# APM32F411 register map
Vendor: Geehy; File version: 2024.11.05
CPU: CM4 r1p0, little endian, 3 interrupt priority bits
Registers are 32-bit, read-write, reset 0x0 unless marked. A register's access mark holds for its fields unless they carry their own. Offsets are from the block's base; [hi:lo] are bit positions; {n}, {i} and the like mark numbered series.

## OTG_FS_PWRCLK — USB on the go full speed
Base 0x50000E00
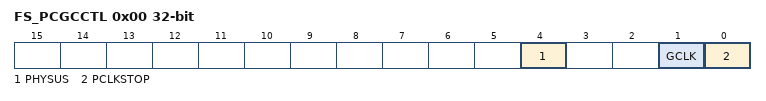
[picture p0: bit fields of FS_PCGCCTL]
0x00 FS_PCGCCTL — OTG_FS power and clock gating control register
  [4] PHYSUS — PHY Suspended
  [1] GCLK — Gate HCLK
  [0] PCLKSTOP — Stop PHY clock

## PMU — Power control
Base 0x40007000
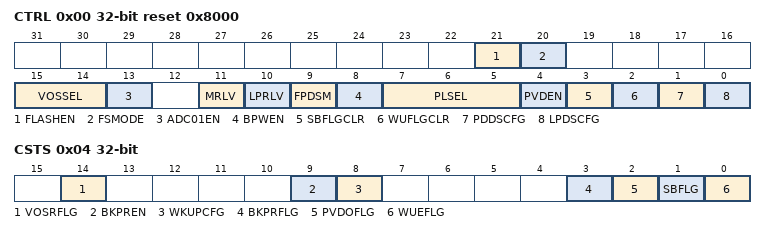
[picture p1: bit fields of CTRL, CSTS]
0x00 CTRL reset 0x8000 — power control register
  [21] FLASHEN — Flash Interface Enable
  [20] FSMODE — Force Flash Sleep Mode
  [15:14] VOSSEL — Regulator Voltage Scaling Output Selection
  [13] ADC01EN — ADC Option 1 Enable
  [11] MRLV — Main Regulator Low Voltage in Stop Mode
  [10] LPRLV — Low Power Regulator Low Voltage in Stop Mode
  [9] FPDSM — Flash power down in Stop mode
  [8] BPWEN — Backup Domain Write Access Enable
  [7:5] PLSEL — PVD level selection
  [4] PVDEN — Power voltage detector enable
  [3] SBFLGCLR — Clear standby flag
  [2] WUFLGCLR — Clear wakeup flag
  [1] PDDSCFG — Power down deepsleep
  [0] LPDSCFG — Low-power deep sleep
0x04 CSTS access per field — power control/status register
  [14] VOSRFLG rw — Regulator voltage scaling output selection ready bit
  [9] BKPREN rw — Backup regulator enable
  [8] WKUPCFG rw — Enable WKUP pin
  [3] BKPRFLG ro — Backup regulator ready
  [2] PVDOFLG ro — PVD output
  [1] SBFLG ro — Standby flag
  [0] WUEFLG ro — Wakeup flag

## QSPI — Quick Serial peripheral interface
Base 0xA0001000
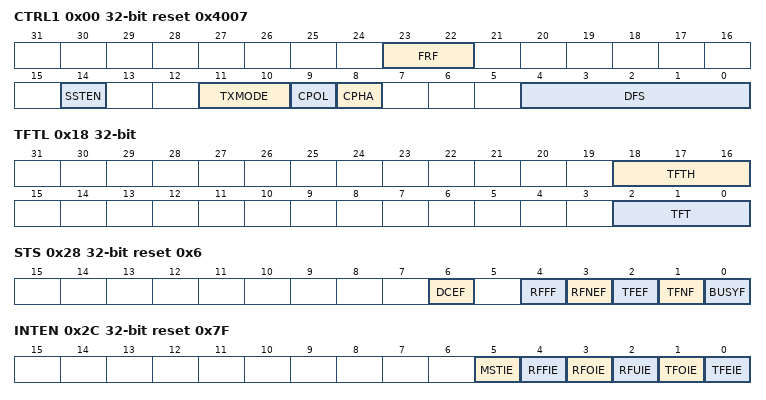
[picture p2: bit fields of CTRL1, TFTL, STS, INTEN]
0x00 CTRL1 reset 0x4007 — Control register 1
  [23:22] FRF, [14] SSTEN, [11:10] TXMODE, [9] CPOL, [8] CPHA, [4:0] DFS
0x04 CTRL2 — Control register 2
  [15:0] NDF
0x08 SSIEN — QSPI Enable register
  [0] EN
0x10 SLAEN — QSPI Slave enable register
  [0] SLAEN
0x14 BR — Baudrate register
  [15:0] CLKDIV
0x18 TFTL — Transmission FIFO threshhold level register
  [18:16] TFTH, [2:0] TFT
0x1C RFTL — Reception FIFO threshhold level register
  [2:0] RFT
0x20 TFL — Transmission FIFO level register
  [2:0] TFL
0x24 RFL — Reception FIFO level register
  [2:0] RFL
0x28 STS reset 0x6 — Status register
  [6] DCEF, [4] RFFF, [3] RFNEF, [2] TFEF, [1] TFNF, [0] BUSYF
0x2C INTEN reset 0x7F — Interrupt enable register
  [5] MSTIE, [4] RFFIE, [3] RFOIE, [2] RFUIE, [1] TFOIE, [0] TFEIE
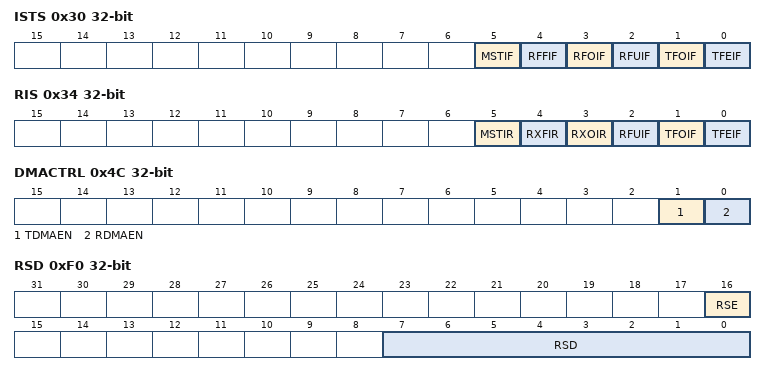
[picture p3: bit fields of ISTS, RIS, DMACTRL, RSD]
0x30 ISTS ro — Interrupt status register
  [5] MSTIF, [4] RFFIF, [3] RFOIF, [2] RFUIF, [1] TFOIF, [0] TFEIF
0x34 RIS ro — Raw interrupt register
  [5] MSTIR, [4] RXFIR, [3] RXOIR, [2] RFUIF, [1] TFOIF, [0] TFEIF
0x38 TFOIC ro — Transmission FIFO overflow interrupt clear register
  [0] TFOIC
0x3C RFOIC ro — Reception FIFO overflow interrupt clear register
  [0] RFOIC
0x40 RFUIC ro — Reception FIFO underflow interrupt clear register
  [0] RFUIC
0x44 MIC ro — Master interrupt clear register
  [0] MIC
0x48 ICF ro — Interrupt clear register
  [0] ICF
0x4C DMACTRL — dma control register
  [1] TDMAEN — Transmit DMA Enable
  [0] RDMAEN — Receive DMA Enable
0x50 DMATDL — dma tx data level register
  [2:0] DMATDL
0x54 DMARDL — dma rx data level register
  [2:0] DMARDL
0x60 DATA
0xF0 RSD — Reception sample register
  [16] RSE, [7:0] RSD
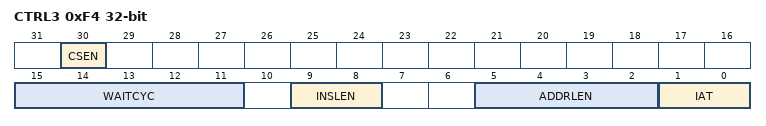
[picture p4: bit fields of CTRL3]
0xF4 CTRL3 — Control register 3
  [30] CSEN, [15:11] WAITCYC, [9:8] INSLEN, [5:2] ADDRLEN, [1:0] IAT
0x200 IOSW — IO switch register
  [0] IOSW — I/O switch

## RNG — Random number generator
Base 0x50060800
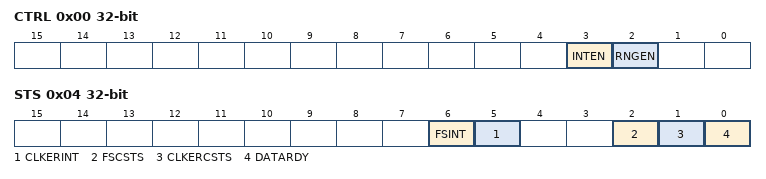
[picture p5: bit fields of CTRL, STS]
0x00 CTRL — control register
  [3] INTEN — Interrupt enable
  [2] RNGEN — Random number generator enable
0x04 STS access per field — status register
  [6] FSINT rw — Seed error interrupt status
  [5] CLKERINT rw — Clock error interrupt status
  [2] FSCSTS ro — Seed error current status
  [1] CLKERCSTS ro — Clock error current status
  [0] DATARDY ro — Data ready
0x08 DATA ro
  [31:0] DATA — Random data

## SYSCFG — System configuration controller
Base 0x40013800
0x00 MMSEL — memory remap register
  [1:0] MMSEL — Memory Mapping Select
0x04 PMCFG — peripheral mode configuration register
  [16] ADCx02EN — ADCx Option 2 Enable
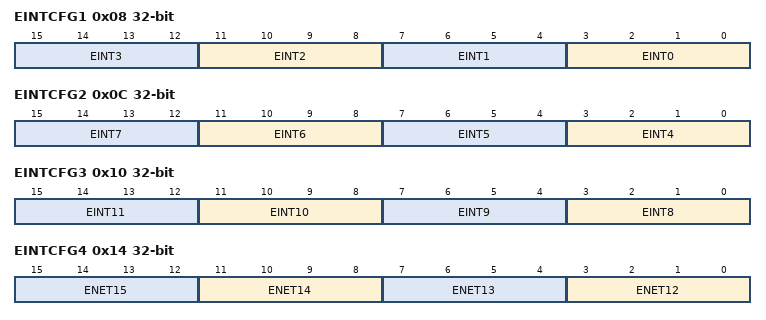
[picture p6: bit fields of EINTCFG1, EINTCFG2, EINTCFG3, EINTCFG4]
0x08 EINTCFG1 — external interrupt configuration register 1
  [4n+3:4n] EINT{n} (n=0..3) — EINTx Configure
0x0C EINTCFG2 — external interrupt configuration register 2
  [4n-13:4n-16] EINT{n} (n=4..7) — EINTx Configure
0x10 EINTCFG3 — external interrupt configuration register 3
  [4n-29:4n-32] EINT{n} (n=8..11) — EINTx Configure
0x14 EINTCFG4 — external interrupt configuration register 4
  [4n-45:4n-48] ENET{n} (n=12..15) — EINTx Configure
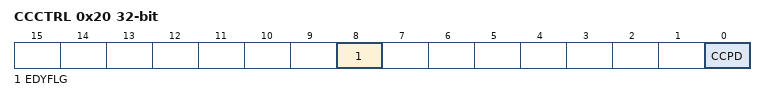
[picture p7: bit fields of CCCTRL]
0x20 CCCTRL access per field — Compensation cell control register
  [8] EDYFLG ro — Compensation Cell Ready Flag
  [0] CCPD rw — Compensation Cell Power-down
